VERSION ""

NS_ :

BS_:

BU_: ECU IVI

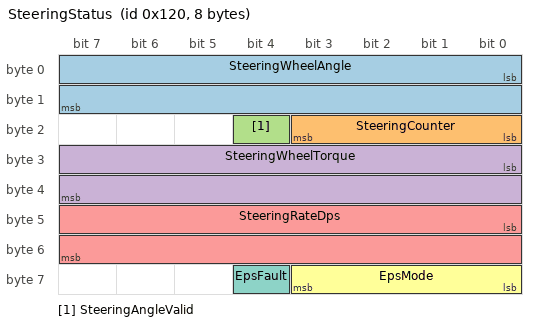
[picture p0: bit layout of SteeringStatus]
BO_ 288 SteeringStatus: 8 ECU
 SG_ SteeringWheelAngle : 0|16@1- (0.1,0) [-3276.8|3276.7] "deg" IVI
 SG_ SteeringCounter : 16|4@1+ (1,0) [0|15] "" IVI
 SG_ SteeringAngleValid : 20|1@1+ (1,0) [0|1] "" IVI
 SG_ SteeringWheelTorque : 24|16@1- (0.01,0) [-327.68|327.67] "Nm" IVI
 SG_ SteeringRateDps : 40|16@1- (0.1,0) [-3276.8|3276.7] "deg/s" IVI
 SG_ EpsMode : 56|4@1+ (1,0) [0|15] "" IVI
 SG_ EpsFault : 60|1@1+ (1,0) [0|1] "" IVI

CM_ "Steering, owned by the EPS (electric power steering) ECU. Always active -
every vehicle steers, whatever propels it - so `requires: []` in the manifest,
like body and hvac. CAN ID range 0x120-0x13F.

SteeringStatus moved here from vehicle.dbc unchanged: identical CAN ID, identical
bit layout for SteeringWheelAngle and SteeringCounter. Only the file and the
owning SOME/IP service changed. The frame is cyclic at 50 Hz because the IVI
integrates the angle for dead reckoning, which is also why the alive counter
matters more here than elsewhere.";
CM_ BO_ 288 "Steering status; cyclic @50Hz (20ms)";
CM_ SG_ 288 SteeringWheelAngle "Absolute hand-wheel angle, 0.1 deg/bit, signed; operating range -720..+720 deg (+ = left/CCW)";
CM_ SG_ 288 SteeringCounter "Rolling alive counter 0..15, +1 per frame, wraps; receiver detects loss via (rx != (prev+1) mod 16)";
CM_ SG_ 288 SteeringAngleValid "0 while the EPS has not yet found the absolute centre after a power cycle. Dead reckoning MUST ignore the angle until this is 1, or it integrates a bogus offset.";
CM_ SG_ 288 SteeringWheelTorque "Driver torque on the hand wheel, 0.01 Nm/bit, signed; the hands-on-wheel signal ADAS needs";
CM_ SG_ 288 SteeringRateDps "Angular rate, 0.1 deg/s per bit, signed";

VAL_ 288 EpsMode 0 "off" 1 "normal" 2 "comfort" 3 "sport" 4 "degraded" ;
